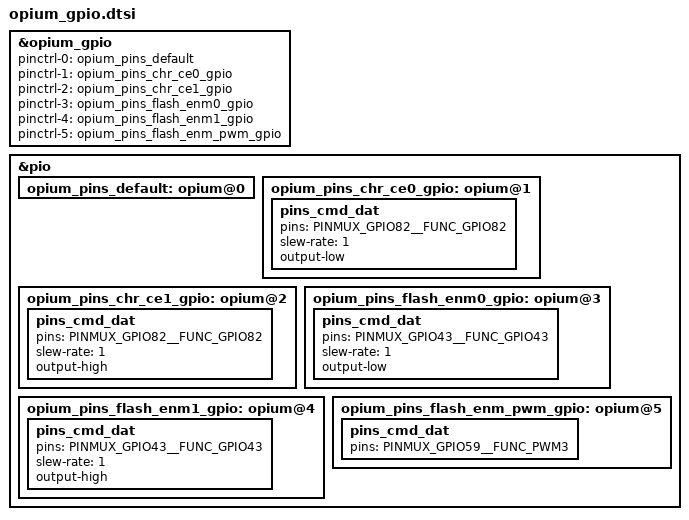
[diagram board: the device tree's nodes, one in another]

&opium_gpio {
	pinctrl-names = "default", "opium_chr_ce0", "opium_chr_ce1", "opium_flash_enm0", "opium_flash_enm1", "opium_flash_enm_pwm";

	pinctrl-0 = <&opium_pins_default>;
	pinctrl-1 = <&opium_pins_chr_ce0_gpio>;
	pinctrl-2 = <&opium_pins_chr_ce1_gpio>;
	pinctrl-3 = <&opium_pins_flash_enm0_gpio>;
	pinctrl-4 = <&opium_pins_flash_enm1_gpio>;
	pinctrl-5 = <&opium_pins_flash_enm_pwm_gpio>;
	status = "okay";
};
&pio {
	opium_pins_default: opium@0 {
	};

	opium_pins_chr_ce0_gpio: opium@1 {
		pins_cmd_dat {
			pins = <PINMUX_GPIO82__FUNC_GPIO82>;
			slew-rate = <1>;
			output-low;
		};
	};
	opium_pins_chr_ce1_gpio: opium@2 {
		pins_cmd_dat {
			pins = <PINMUX_GPIO82__FUNC_GPIO82>;
			slew-rate = <1>;
			output-high;
		};
	};
	opium_pins_flash_enm0_gpio: opium@3 {
		pins_cmd_dat {
			pins = <PINMUX_GPIO43__FUNC_GPIO43>;
			slew-rate = <1>;
			output-low;
		};
	};
	opium_pins_flash_enm1_gpio: opium@4 {
		pins_cmd_dat {
			pins = <PINMUX_GPIO43__FUNC_GPIO43>;
			slew-rate = <1>;
			output-high;
		};
	};
	opium_pins_flash_enm_pwm_gpio: opium@5 {
		pins_cmd_dat {
			pins = <PINMUX_GPIO59__FUNC_PWM3>;
		};
	};
};
